# MINI51XAE_v1 register map
File version: 1.0
Registers are 32-bit, read-write, reset 0x0 unless marked. A register's access mark holds for its fields unless they carry their own. Offsets are from the block's base; [hi:lo] are bit positions; {n}, {i} and the like mark numbered series; 'fields as' and 'values as' point back to an identical list.

## I2C — I2C Register Map
Base 0x40020000
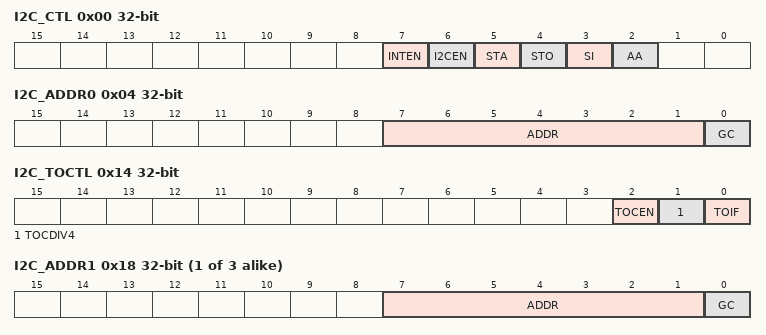
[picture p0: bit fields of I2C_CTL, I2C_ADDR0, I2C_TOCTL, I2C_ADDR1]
0x00 I2C_CTL — I2C Control Register
  [7] INTEN — Enable Interrupt
    0=I2C interrupt Disabled; 1=I2C interrupt Enabled
  [6] I2CEN — I2C Controller Enable Bit
    0=I2C Controller Disabled; 1=I2C Controller Enabled
  [5] STA — I2C START Control Bit. Setting STA to logic 1 to enter Master mode. I2C hardware sends a START or repeats the START condition to bus when the bus is free.
  [4] STO — I2C STOP Control Bit. In Master mode, setting STO to transmit a STOP condition to bus then I2C hardware will check the bus condition if a STOP condition is detected this bit will be cleared by hardware automatically. In Slave mode, setting STO resets I2C hardware to the defined "not addressed" Slave mode. This means it is NO LONGER in the Slave receiver mode to receive data from the master transmit device.
  [3] SI — I2C Interrupt Flag. When a new I2C state is present in the I2C_STATUS register, the SI flag is set by hardware, and if bit INTEN (I2C_CTL[7]) is set, the I2C interrupt is requested. SI must be cleared by software. Software can write 1 to clear this bit.
  [2] AA — Assert Acknowledge Control Bit
0x04 I2C_ADDR0 — I2C Slave Address Register 0
  [7:1] ADDR — I2C Address Register. The content of this register is irrelevant when I2C is in Master mode. In Slave mode, the seven most significant bits must be loaded with the MCU's own address. The I2C hardware will react if either of the address is matched.
  [0] GC — General Call Function
    0=General Call Function Disabled; 1=General Call Function Enabled
0x08 I2C_DAT — I2C Data Register
  [7:0] DAT — I2C Data Register. Bit [7:0] is located with the 8-bit transferred data of the I2C serial port.
0x0C I2C_STATUS ro reset 0xF8
  [7:0] STATUS
0x10 I2C_CLKDIV — I2C Clock Divided Register
  [7:0] DIVIDER — I2C Clock Divided Register. Note: The minimum value of DIVIDER is 4.
0x14 I2C_TOCTL — I2C Time-Out Counter Register
  [2] TOCEN — Time-Out Counter Enabled. Note: When the 14-bit time-out counter is enabled, it will start counting when SI is clear. Setting 1to the SI flag will reset counter and re-start up counting after SI is cleared.
    0=Time-out counter Disabled; 1=Time-out counter Enabled
  [1] TOCDIV4 — Time-Out Counter Input Clock Divided By 4. Note: When enabled, the time-out period is extended 4 times.
    0=Time-out counter input clock divided by 4 Disabled; 1=Time-out counter input clock divided by 4 Enabled
  [0] TOIF — Time-Out Flag. This bit is set by hardware when I2C time-out happened and it can interrupt CPU if I2C interrupt enable bit (INTEN) is set to 1. Note: Software can write 1 to clear this bit.
{0x14+4i} I2C_ADDR{i} (i=1..3) — I2C Slave Address Register {i}
  fields as I2C_ADDR0
{0x24+4i} I2C_ADDRMSK{i} (i=0..3) — I2C Slave Address Mask Register {i}
  [7:1] ADDRMSK — I2C Address Mask Register
    0=I2C address mask Disabled (the received corresponding register bit should be exactly the same as address register); 1=I2C address mask Enabled (the received corresponding address bit is "Don't care")
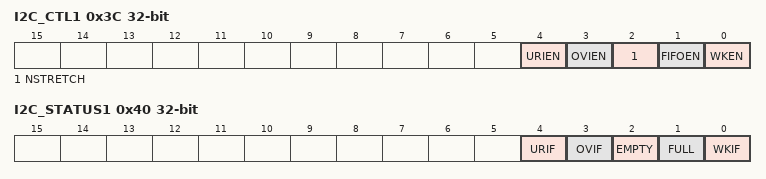
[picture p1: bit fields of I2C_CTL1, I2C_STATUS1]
0x3C I2C_CTL1 — I2C Control Register 1
  [4] URIEN — I2C UNDER RUN Interrupt Control Bit. Setting URIEN to enable will send a interrupt to system when the TWOFF bit is enabled and there is under run event happened in transmitted FIFO.
    0=Disabled; 1=Enabled
  [3] OVIEN — I2C OVER RUN Interrupt Control Bit. Setting OVIEN to enable will send a interrupt to system when the TWOFF bit is enabled and there is over run event in received FIFO.
    0=Disabled; 1=Enabled
  [2] NSTRETCH — NO STRETCH The I2C BUS
    0=The I2C SCL bus is stretched by hardware if the SI is not cleared in master mode; 1=The I2C SCL bus is not stretched by hardware if the SI is not cleared in master mode
  [1] FIFOEN — FIFO Mode Enable
    0=Disabled; 1=Enabled
  [0] WKEN — Wake-Up Enable. The system can be wake up by I2C bus when the system is set into power mode and the received data matched one of the addresses in Address Register.
    0=I2C wake up function Disabled; 1=I2C wake up function Enabled
0x40 I2C_STATUS1 — I2C Status Register 1
  [4] URIF — I2C UNDER RUN Status Bit
  [3] OVIF — I2C OVER RUN Status Bit
  [2] EMPTY — I2C TWO LEVEL FIFO EMPTY
  [1] FULL — I2C TWO LEVEL FIFO FULL
  [0] WKIF — I2C Wake-Up Interrupt Flag. When chip is woken up from Power-Down mode by I2C, this bit is set to 1. Software can write 1 to clear this bit.
